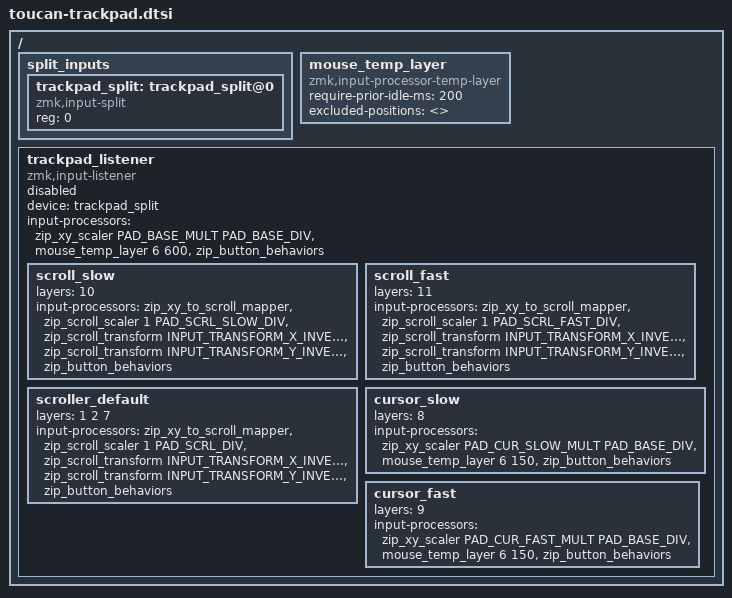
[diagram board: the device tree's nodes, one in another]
/*
 * 觸控板：速度參數 + input-split proxy + 自動升層 + 處理鏈。
 *
 * 這個檔案被「central」和「持有感測器的 peripheral」兩邊 include：
 *   toucan_left.overlay   — central，把 trackpad_listener 設 okay
 *   toucan.dtsi           — 給 toucan_right / toucan_dongle
 *
 * trackpad_split 兩邊都要有，而且 reg 必須一致（都是 0）：peripheral 那側
 * 由 toucan_right.overlay 把它綁到真正的感測器，central 這側它是接收端的
 * proxy。listener 只在 central 上 status = "okay"。
 *
 * 2026-09-03：感測器從 Cirque Pinnacle 換成 Azoteq TPS43（這台是 toucan2），
 * 節點名跟著上游 beekeeb 改成 trackpad_*。**底下整條處理鏈完全沒動**——
 * zip_xy_scaler / zip_scroll_scaler / temp-layer 都是 ZMK 通用的 input
 * processor，跟 driver 無關，所以三檔調速與自動升層原封不動搬過來。
 * 唯一要留意的是方位：INPUT_TRANSFORM_*_INVERT 那幾個當年是配合 Cirque
 * 調出來的，換感測器後可能要翻，見 toucan_right.overlay 的方位註解。
 */

#include <input/processors.dtsi>
#include <dt-bindings/zmk/input_transform.h>

/*
 * ─── 觸控板速度：兩檔由 base 推導 ────────────────────────────────────────
 *
 * 只要調下面那組「手調」的數字，游標與滾動的兩檔都會跟著同步。devicetree 的
 * cell 支援括號內算式，所以推導可以直接寫在這裡。
 *
 * 對應的 marker layer（見 config/toucan.keymap）：
 *   8  CUR-   9  CUR+     （PAD(6) 拇指 38/39 = 慢、37/40 = 快）
 *   10 SCR-  11 SCR+      （SCRL(7) 拇指同上）
 *
 * ── 2026-09-04 的三處改動 ────────────────────────────────────────────
 *
 *   1. 三檔收成兩檔。舊的中檔（CUR / SCR）刪掉，**留下的慢檔直接繼承中檔的
 *      數值**——舊的最慢檔 0.62x / 25% 實測鈍到不堪用。
 *   2. 游標和滾動的百分比**拆成兩組**（PAD_CUR_*_PCT / PAD_SCRL_*_PCT）。
 *      以前共用一組，現在滾動的快檔要 200%、游標只要 150%，共用會綁死。
 *   3. `PAD_SCRL_DIV` 9 -> 18，一般滾動速度減半（使用者回報按住 G/H 時
 *      觸控板滾太快）。⚠️ 這條鏈 NAV(1) / NUM(2) 也共用，那兩層一起變慢。
 *      改完之後新的預設 = 舊的中檔，新的快檔 = 舊的預設，沒有任何檔位比
 *      改版前的預設更快。
 */

/* ── 手調 ── */
#define PAD_BASE_MULT      250     /* 一般游標 = 250/100 = 2.50x */
#define PAD_BASE_DIV       100
#define PAD_CUR_SLOW_PCT    50     /* 游標慢檔 = base 的 50%  -> 1.25x */
#define PAD_CUR_FAST_PCT   150     /* 游標快檔 = base 的 150% -> 3.75x */
#define PAD_SCRL_DIV        18     /* 一般滾動 zip_scroll_scaler 1 N，N 越大越慢 */
#define PAD_SCRL_SLOW_PCT   50     /* 滾動慢檔 = 一般滾動的 50%  */
#define PAD_SCRL_FAST_PCT  200     /* 滾動快檔 = 一般滾動的 200% */

/* ── 推導，不要手改 ── */
#define PAD_CUR_SLOW_MULT  (PAD_BASE_MULT * PAD_CUR_SLOW_PCT / 100)   /* 125 */
#define PAD_CUR_FAST_MULT  (PAD_BASE_MULT * PAD_CUR_FAST_PCT / 100)   /* 375 */
#define PAD_SCRL_SLOW_DIV  (PAD_SCRL_DIV * 100 / PAD_SCRL_SLOW_PCT)   /*  36 */
#define PAD_SCRL_FAST_DIV  (PAD_SCRL_DIV * 100 / PAD_SCRL_FAST_PCT)   /*   9 */

/ {
    split_inputs {
        #address-cells = <1>;
        #size-cells = <0>;

        trackpad_split: trackpad_split@0 {
            compatible = "zmk,input-split";
            reg = <0>;
        };
    };

    /*
     * 自動升起 PAD 層（6）的處理器。
     *
     * timeout 150 ms = 「最後一次觸控板移動之後，layer 6 還留多久」。手指停
     * 在板上不會產生移動事件，所以這個值不能再縮——縮了會直接壞掉「先定位、
     * 停手、再按鍵」，包含 layer 6 位置 26/27/28 的 &mkp LCLK/RCLK/MCLK。
     *
     * excluded-positions 刻意留空——語意是「沒有任何鍵能提前結束滑鼠層」，
     * 只有 timeout 到了才會關。這是 ZMK 上游的常見做法（見 ergohaven/
     * ergohaven-zmk 的 velvet_v3_ui.keymap）。
     *
     * ⚠️ 空清單不是「每個鍵都關層」，是「沒有鍵會關層」——語意跟直覺相反。
     * 原因在編譯期，見 zmk/app/src/pointing/input_processor_temp_layer.c：
     *
     *   #define NEEDS_POSITION_HANDLERS(n, ...) \
     *       DT_INST_PROP_HAS_IDX(n, excluded_positions, 0)
     *   #if DT_INST_FOREACH_STATUS_OKAY_VARGS(NEEDS_POSITION_HANDLERS, ||)
     *   ZMK_SUBSCRIPTION(processor_temp_layer, zmk_position_state_changed);
     *   #endif
     *
     * 清單為空 ⇒ 連 zmk_position_state_changed 都不訂閱 ⇒ 按鍵事件根本到不了
     * 這個 processor。順帶少一次 per-keypress 的線性搜尋。
     *
     * 為什麼改成空的：原本列了 34 個位置，而「沒被列到」的只有 0/11/12/22/
     * 23/24/34/35，其中 6 個沒焊開關——實際上只有位置 22 和 34 會關層，等於
     * 已經接近「沒有鍵會關層」。但那份名單必須跟 layer 6/7 的 bindings 手動
     * 同步（尤其六顆拇指調速鍵，漏了就按不到），是純粹的維護負擔。拿掉之後
     * 動 bindings 不用再回來改這裡。
     *
     * 空清單本身「不」解決「用完觸控板打字誤觸」——那個問題的根源是 layer 6
     * 裝了什麼，不是誰能關層。已經一併處理：layer 6 現在只留點擊、六顆調速
     * 拇指和位置 10 的 &to 0，共 11 格，其餘 31 格全 &trans，進階操作搬到
     * SCRL (7)。
     * 詳見 config/toucan.keymap 的 layer_6 註解。
     *
     * require-prior-idle-ms 是反方向的保護：剛打過字的 N ms 內，觸控板不會
     * 升起 layer 6（游標仍會動，但點擊鍵不在）。200 ms 對齊 QMK 的
     * AUTO_MOUSE_DELAY 預設值（= TAPPING_TERM）。跟上面那件事無關。
     *
     * layer 6 瘦身之後，把下面 listener 的 timeout（目前 150）拉長變成安全的
     * 選項——誤按的代價已經只是「打出原本那個字」。ergohaven 用 500、QMK 的
     * AUTO_MOUSE_TIME 預設 650。想要「先定位、停手、再點擊」更穩就往上調。
     */
    /omit-if-no-ref/ mouse_temp_layer: mouse_temp_layer {
        compatible = "zmk,input-processor-temp-layer";
        #input-processor-cells = <2>;
        require-prior-idle-ms = <200>;
        excluded-positions = <>;
    };

    /*
     * 觸控板處理鏈。只在 central 上跑（toucan_left.overlay 把它設 okay）。
     *
     * 子節點是「第一個命中的取代整條 base 鏈」——不是疊加。所以：
     *   1. 宣告順序 = 優先權。滾動的兩檔排在 scroller_default 之前，
     *      cursor_* 排在它之後（否則按住 ESC 進 NAV 時會被搶走）。
     *   2. 每一條鏈都必須帶 &zip_button_behaviors，漏掉的那幾層會重新
     *      開放 tap-and-drag（見 config/toucan.keymap 檔頭的說明）。
     *   3. 兩條 cursor_* 都必須帶 &mouse_temp_layer，否則按住調速鍵時
     *      layer 6 的 timeout 不會續期，滑到一半層就掉下去了。
     *
     * ⚠️ 這些 `layers = <>` 是寫死的 layer index，config/toucan.keymap 加層 /
     *    刪層 / 重排層一定要回來同步。2026-09-04 那次（17 -> 13 層）就是連
     *    這裡一起改的：11 -> 10、13 -> 11、10 -> 9，並刪掉舊的 scroll_slow
     *    (12) 和 cursor_slow (9) 兩條鏈。
     */
    trackpad_listener: trackpad_listener {
        compatible = "zmk,input-listener";
        status = "disabled";
        device = <&trackpad_split>;

        input-processors = <&zip_xy_scaler PAD_BASE_MULT PAD_BASE_DIV &mouse_temp_layer 6 600 &zip_button_behaviors>;

        scroll_slow {
            layers = <10>;
            input-processors = <
                &zip_xy_to_scroll_mapper
                &zip_scroll_scaler 1 PAD_SCRL_SLOW_DIV
                &zip_scroll_transform INPUT_TRANSFORM_X_INVERT
                &zip_scroll_transform INPUT_TRANSFORM_Y_INVERT
                &zip_button_behaviors
            >;
        };

        scroll_fast {
            layers = <11>;
            input-processors = <
                &zip_xy_to_scroll_mapper
                &zip_scroll_scaler 1 PAD_SCRL_FAST_DIV
                &zip_scroll_transform INPUT_TRANSFORM_X_INVERT
                &zip_scroll_transform INPUT_TRANSFORM_Y_INVERT
                &zip_button_behaviors
            >;
        };

        // 一般滾動。7 = SCRL（BASE 按住 G / H 進入）、1 = NAV、2 = NUM。
        scroller_default {
            layers = <1 2 7>;
            input-processors = <
                &zip_xy_to_scroll_mapper
                &zip_scroll_scaler 1 PAD_SCRL_DIV
                &zip_scroll_transform INPUT_TRANSFORM_X_INVERT
                &zip_scroll_transform INPUT_TRANSFORM_Y_INVERT
                &zip_button_behaviors
            >;
        };

        cursor_slow {
            layers = <8>;
            input-processors = <&zip_xy_scaler PAD_CUR_SLOW_MULT PAD_BASE_DIV &mouse_temp_layer 6 150 &zip_button_behaviors>;
        };

        cursor_fast {
            layers = <9>;
            input-processors = <&zip_xy_scaler PAD_CUR_FAST_MULT PAD_BASE_DIV &mouse_temp_layer 6 150 &zip_button_behaviors>;
        };
    };
};
